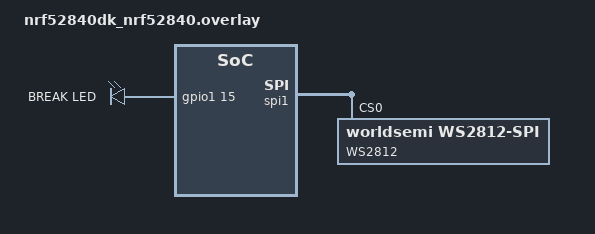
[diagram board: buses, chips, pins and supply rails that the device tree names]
/*
 * Copyright (c) 2019, Nordic Semiconductor ASA
 *
 * SPDX-License-Identifier: Apache-2.0
 */

#include <dt-bindings/led/led.h>

#include "../nrf-ws2812-bindings.h"

/*
 * Overrite spi1 -> is already
 * enabled in the default dt file
 *
 *  &spi1 {
	 *        compatible = "nordic,nrf-spi";
	 *        status = "okay";
	 *        sck-pin = <31>;
	 *        mosi-pin = <30>; -> connect LED-DataIn
	 *        miso-pin = <40>;
 *    };
 */

&spi1 {
	compatible = "nordic,nrf-spim";

	led_strip: ws2812@0 {
		compatible = "worldsemi,ws2812-spi";
		label = "WS2812";

		/* SPI */
		reg = <0>; /* ignored, but necessary for SPI bindings */
		spi-max-frequency = <SPI_FREQ>;

		/* WS2812 */
		chain-length = <PIXEL_COUNT>;
		color-mapping = <LED_COLOR_ID_GREEN
		LED_COLOR_ID_RED
		LED_COLOR_ID_BLUE
		LED_COLOR_ID_WHITE>;
		spi-one-frame = <ONE_FRAME>;
		spi-zero-frame = <ZERO_FRAME>;
	};
};

/ {
	aliases {
		led-strip = &led_strip;
	};
};


/ {
	signal_leds:signal_leds {
		compatible = "gpio-leds";
		break_led {
			gpios = <&gpio1 15 GPIO_ACTIVE_HIGH>;
			label = "BREAK LED";
		};
	};
};
